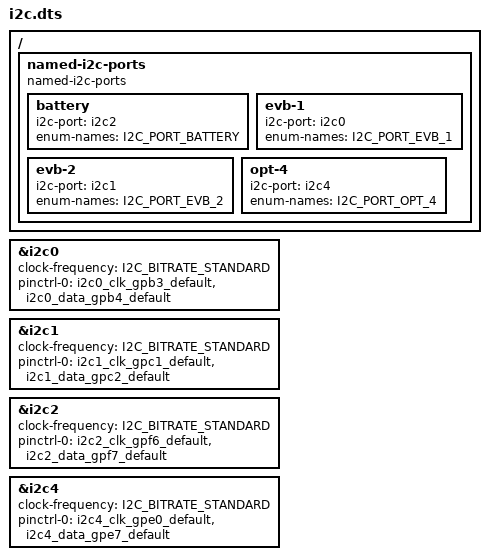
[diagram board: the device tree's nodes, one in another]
/* Copyright 2022 The ChromiumOS Authors
 * Use of this source code is governed by a BSD-style license that can be
 * found in the LICENSE file.
 */

/ {
	named-i2c-ports {
		compatible = "named-i2c-ports";

		battery {
			i2c-port = <&i2c2>;
			enum-names = "I2C_PORT_BATTERY";
		};
		evb-1 {
			i2c-port = <&i2c0>;
			enum-names = "I2C_PORT_EVB_1";
		};
		evb-2 {
			i2c-port = <&i2c1>;
			enum-names = "I2C_PORT_EVB_2";
		};
		opt-4 {
			i2c-port = <&i2c4>;
			enum-names = "I2C_PORT_OPT_4";
		};
	};
};

&i2c0 {
	status = "okay";
	clock-frequency = <I2C_BITRATE_STANDARD>;
	pinctrl-0 = <&i2c0_clk_gpb3_default
		     &i2c0_data_gpb4_default>;
	pinctrl-names = "default";
};

&i2c1 {
	status = "okay";
	clock-frequency = <I2C_BITRATE_STANDARD>;
	pinctrl-0 = <&i2c1_clk_gpc1_default
		     &i2c1_data_gpc2_default>;
	pinctrl-names = "default";
};

&i2c2 {
	status = "okay";
	clock-frequency = <I2C_BITRATE_STANDARD>;
	pinctrl-0 = <&i2c2_clk_gpf6_default
		     &i2c2_data_gpf7_default>;
	pinctrl-names = "default";
};

&i2c4 {
	status = "okay";
	clock-frequency = <I2C_BITRATE_STANDARD>;
	pinctrl-0 = <&i2c4_clk_gpe0_default
		     &i2c4_data_gpe7_default>;
	pinctrl-names = "default";
};
